# STM32H733xx register map
File version: 1.0
Registers are 32-bit, access not given, reset 0x0 unless marked. A register's access mark holds for its fields unless they carry their own. Offsets are from the block's base; [hi:lo] are bit positions; {n}, {i} and the like mark numbered series.

## DCMI
Base 0x48020000
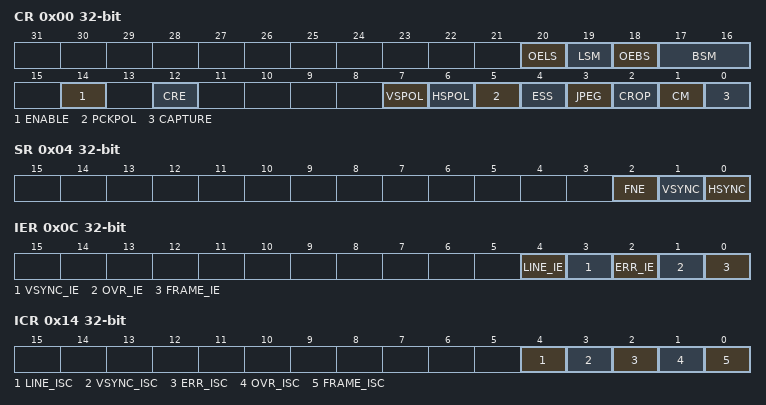
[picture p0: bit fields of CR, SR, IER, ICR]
0x00 CR
  [20] OELS, [19] LSM, [18] OEBS, [17:16] BSM, [14] ENABLE, [12] CRE, [7] VSPOL, [6] HSPOL, [5] PCKPOL, [4] ESS, [3] JPEG, [2] CROP, [1] CM, [0] CAPTURE
0x04 SR
  [2] FNE, [1] VSYNC, [0] HSYNC
0x08 RISR
0x0C IER
  [4] LINE_IE, [3] VSYNC_IE, [2] ERR_IE, [1] OVR_IE, [0] FRAME_IE
0x10 MISR
0x14 ICR
  [4] LINE_ISC, [3] VSYNC_ISC, [2] ERR_ISC, [1] OVR_ISC, [0] FRAME_ISC
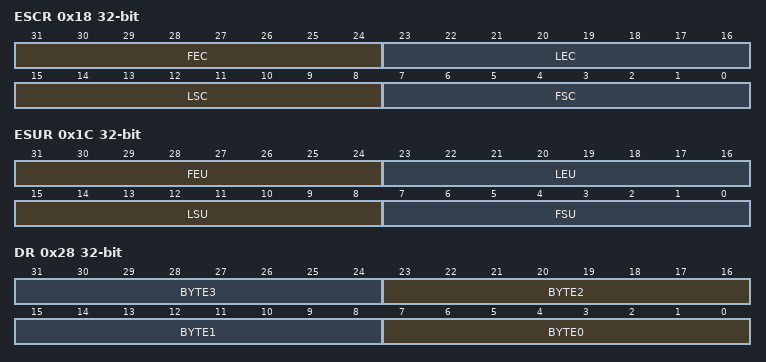
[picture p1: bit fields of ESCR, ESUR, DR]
0x18 ESCR
  [31:24] FEC, [23:16] LEC, [15:8] LSC, [7:0] FSC
0x1C ESUR
  [31:24] FEU, [23:16] LEU, [15:8] LSU, [7:0] FSU
0x20 CWSTRTR
0x24 CWSIZER
0x28 DR
  [8n+7:8n] BYTE{n} (n=0..3)

## PSSI
Base 0x48020400
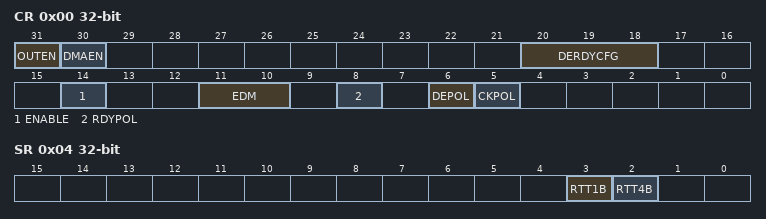
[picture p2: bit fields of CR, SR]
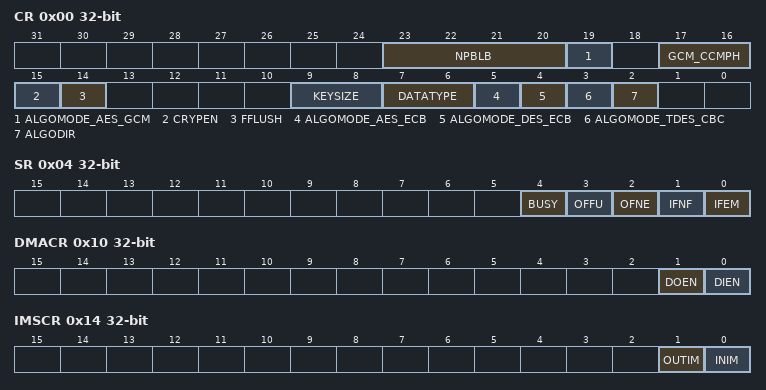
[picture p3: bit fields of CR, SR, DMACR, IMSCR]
0x00 CR
  [31] OUTEN, [30] DMAEN, [20:18] DERDYCFG, [14] ENABLE, [11:10] EDM, [8] RDYPOL, [6] DEPOL, [5] CKPOL
0x04 SR
  [3] RTT1B, [2] RTT4B
0x08 RIS
  [1] OVR_RIS
0x0C IER
  [1] OVR_IE
0x10 MIS
  [1] OVR_MIS
0x14 ICR
  [1] OVR_ISC
0x28 DR
0x3F0 HWCFGR
0x3F4 VERR
0x3F8 IPIDR
0x3FC SIDR

## CRYP
Base 0x48021000
0x00 CR
  [23:20] NPBLB, [19] ALGOMODE_AES_GCM, [17:16] GCM_CCMPH, [15] CRYPEN, [14] FFLUSH, [9:8] KEYSIZE, [7:6] DATATYPE, [5] ALGOMODE_AES_ECB, [4] ALGOMODE_DES_ECB, [3] ALGOMODE_TDES_CBC, [2] ALGODIR
0x04 SR
  [4] BUSY, [3] OFFU, [2] OFNE, [1] IFNF, [0] IFEM
0x08 DIN
0x0C DOUT
0x10 DMACR
  [1] DOEN, [0] DIEN
0x14 IMSCR
  [1] OUTIM, [0] INIM
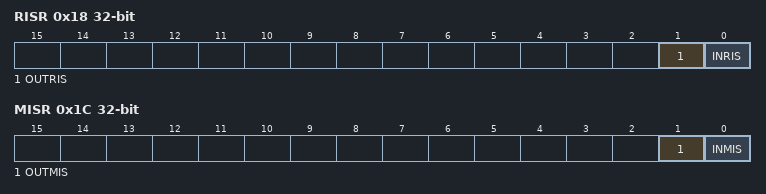
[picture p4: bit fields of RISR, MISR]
0x18 RISR
  [1] OUTRIS, [0] INRIS
0x1C MISR
  [1] OUTMIS, [0] INMIS
{0x20+8i} K{i}LR (i=0..3)
{0x24+8i} K{i}RR (i=0..3)
0x40 IV0LR
0x44 IV0RR
0x48 IV1LR
0x4C IV1RR
{0x50+4i} CSGCMCCM{i}R (i=0..7)
{0x70+4i} CSGCM{i}R (i=0..7)

## HASH
Base 0x48021400
0x00 CR
  [16] LKEY, [13] MDMAT, [12] DINNE, [11:8] NBW, [18:7] ALGO, [6] MODE, [5:4] DATATYPE, [3] DMAE, [2] INIT
0x04 DIN
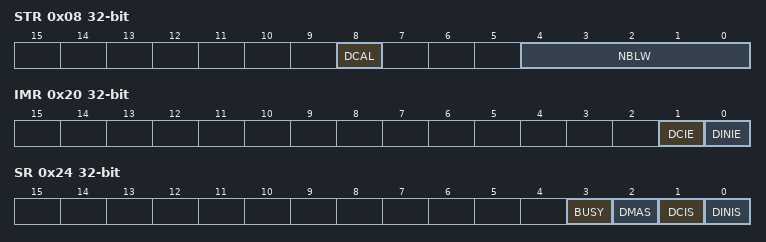
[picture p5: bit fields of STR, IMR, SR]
0x08 STR
  [8] DCAL, [4:0] NBLW
0x0C HR.0
0x10 HR.1
0x14 HR.2
0x18 HR.3
0x1C HR.4
0x20 IMR
  [1] DCIE, [0] DINIE
0x24 SR
  [3] BUSY, [2] DMAS, [1] DCIS, [0] DINIS
0xF8 CSR.0
0xFC CSR.1
0x100 CSR.2
0x104 CSR.3
0x108 CSR.4
0x10C CSR.5
0x110 CSR.6
0x114 CSR.7
0x118 CSR.8
0x11C CSR.9
0x120 CSR.10
0x124 CSR.11
0x128 CSR.12
0x12C CSR.13
0x130 CSR.14
0x134 CSR.15
0x138 CSR.16
0x13C CSR.17
0x140 CSR.18
0x144 CSR.19
0x148 CSR.20
0x14C CSR.21
0x150 CSR.22
0x154 CSR.23
0x158 CSR.24
0x15C CSR.25
0x160 CSR.26
0x164 CSR.27
0x168 CSR.28
0x16C CSR.29
0x170 CSR.30
0x174 CSR.31
0x178 CSR.32
0x17C CSR.33
0x180 CSR.34
0x184 CSR.35
0x188 CSR.36
0x18C CSR.37
0x190 CSR.38
0x194 CSR.39
0x198 CSR.40
0x19C CSR.41
0x1A0 CSR.42
0x1A4 CSR.43
0x1A8 CSR.44
0x1AC CSR.45
0x1B0 CSR.46
0x1B4 CSR.47
0x1B8 CSR.48
0x1BC CSR.49
0x1C0 CSR.50
0x1C4 CSR.51
0x1C8 CSR.52
0x1CC CSR.53

## HASH_DIGEST
Base 0x48021710
0x00 HR.0
0x04 HR.1
0x08 HR.2
0x0C HR.3
0x10 HR.4
0x14 HR.5
0x18 HR.6
0x1C HR.7

## RNG
Base 0x48021800
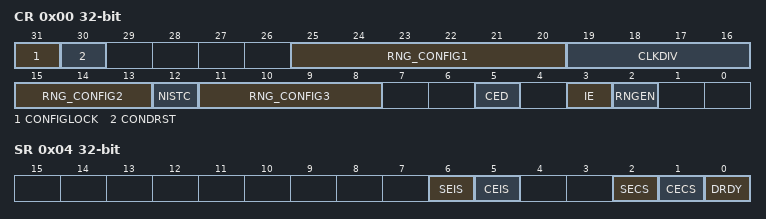
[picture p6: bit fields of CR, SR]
0x00 CR
  [31] CONFIGLOCK, [30] CONDRST, [25:20] RNG_CONFIG1, [19:16] CLKDIV, [15:13] RNG_CONFIG2, [12] NISTC, [11:8] RNG_CONFIG3, [5] CED, [3] IE, [2] RNGEN
0x04 SR
  [6] SEIS, [5] CEIS, [2] SECS, [1] CECS, [0] DRDY
0x08 DR
0x10 HTCR

## SDMMC2
Base 0x48022400
Same registers: SDMMC1 0x52007000
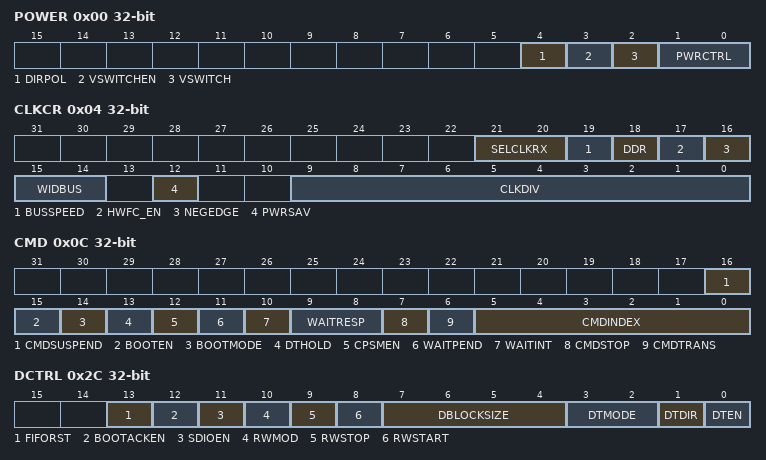
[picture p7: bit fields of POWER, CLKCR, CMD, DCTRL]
0x00 POWER
  [4] DIRPOL, [3] VSWITCHEN, [2] VSWITCH, [1:0] PWRCTRL
0x04 CLKCR
  [21:20] SELCLKRX, [19] BUSSPEED, [18] DDR, [17] HWFC_EN, [16] NEGEDGE, [15:14] WIDBUS, [12] PWRSAV, [9:0] CLKDIV
0x08 ARG
  [31:0] CMDARG
0x0C CMD
  [16] CMDSUSPEND, [15] BOOTEN, [14] BOOTMODE, [13] DTHOLD, [12] CPSMEN, [11] WAITPEND, [10] WAITINT, [9:8] WAITRESP, [7] CMDSTOP, [6] CMDTRANS, [5:0] CMDINDEX
0x10 RESPCMD
  [5:0] RESPCMD
{0x10+4i} RESP{i} (i=1..4)
  [31:0] CARDSTATUS{i}
0x24 DTIMER
  [31:0] DATATIME
0x28 DLEN
  [24:0] DATALENGTH
0x2C DCTRL
  [13] FIFORST, [12] BOOTACKEN, [11] SDIOEN, [10] RWMOD, [9] RWSTOP, [8] RWSTART, [7:4] DBLOCKSIZE, [3:2] DTMODE, [1] DTDIR, [0] DTEN
0x30 DCOUNT
  [24:0] DATACOUNT
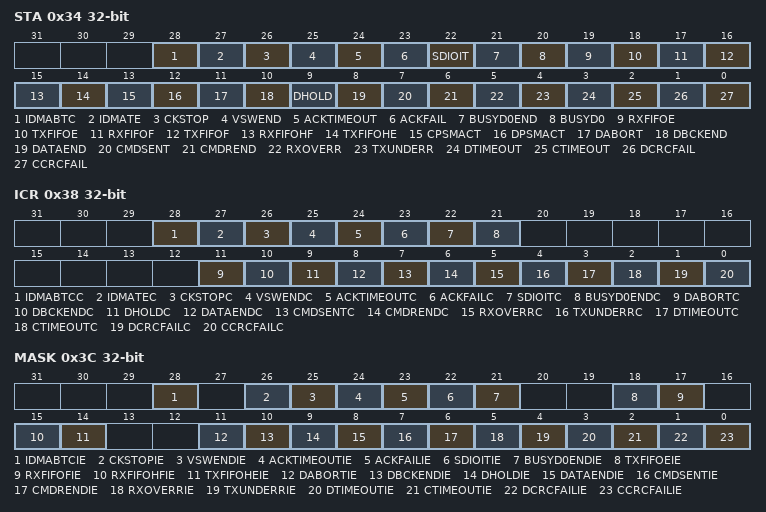
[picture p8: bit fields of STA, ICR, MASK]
0x34 STA
  [28] IDMABTC, [27] IDMATE, [26] CKSTOP, [25] VSWEND, [24] ACKTIMEOUT, [23] ACKFAIL, [22] SDIOIT, [21] BUSYD0END, [20] BUSYD0, [19] RXFIFOE, [18] TXFIFOE, [17] RXFIFOF, [16] TXFIFOF, [15] RXFIFOHF, [14] TXFIFOHE, [13] CPSMACT, [12] DPSMACT, [11] DABORT, [10] DBCKEND, [9] DHOLD, [8] DATAEND, [7] CMDSENT, [6] CMDREND, [5] RXOVERR, [4] TXUNDERR, [3] DTIMEOUT, [2] CTIMEOUT, [1] DCRCFAIL, [0] CCRCFAIL
0x38 ICR
  [28] IDMABTCC, [27] IDMATEC, [26] CKSTOPC, [25] VSWENDC, [24] ACKTIMEOUTC, [23] ACKFAILC, [22] SDIOITC, [21] BUSYD0ENDC, [11] DABORTC, [10] DBCKENDC, [9] DHOLDC, [8] DATAENDC, [7] CMDSENTC, [6] CMDRENDC, [5] RXOVERRC, [4] TXUNDERRC, [3] DTIMEOUTC, [2] CTIMEOUTC, [1] DCRCFAILC, [0] CCRCFAILC
0x3C MASK
  [28] IDMABTCIE, [26] CKSTOPIE, [25] VSWENDIE, [24] ACKTIMEOUTIE, [23] ACKFAILIE, [22] SDIOITIE, [21] BUSYD0ENDIE, [18] TXFIFOEIE, [17] RXFIFOFIE, [15] RXFIFOHFIE, [14] TXFIFOHEIE, [11] DABORTIE, [10] DBCKENDIE, [9] DHOLDIE, [8] DATAENDIE, [7] CMDSENTIE, [6] CMDRENDIE, [5] RXOVERRIE, [4] TXUNDERRIE, [3] DTIMEOUTIE, [2] CTIMEOUTIE, [1] DCRCFAILIE, [0] CCRCFAILIE
0x40 ACKTIME
  [24:0] ACKTIME
0x50 IDMACTRL
0x54 IDMABSIZE
  [12:5] IDMABNDT
0x58 IDMABASE0
0x5C IDMABASE1
0x80 FIFO
  [31:0] FIFODATA
0x3FC IPVR
